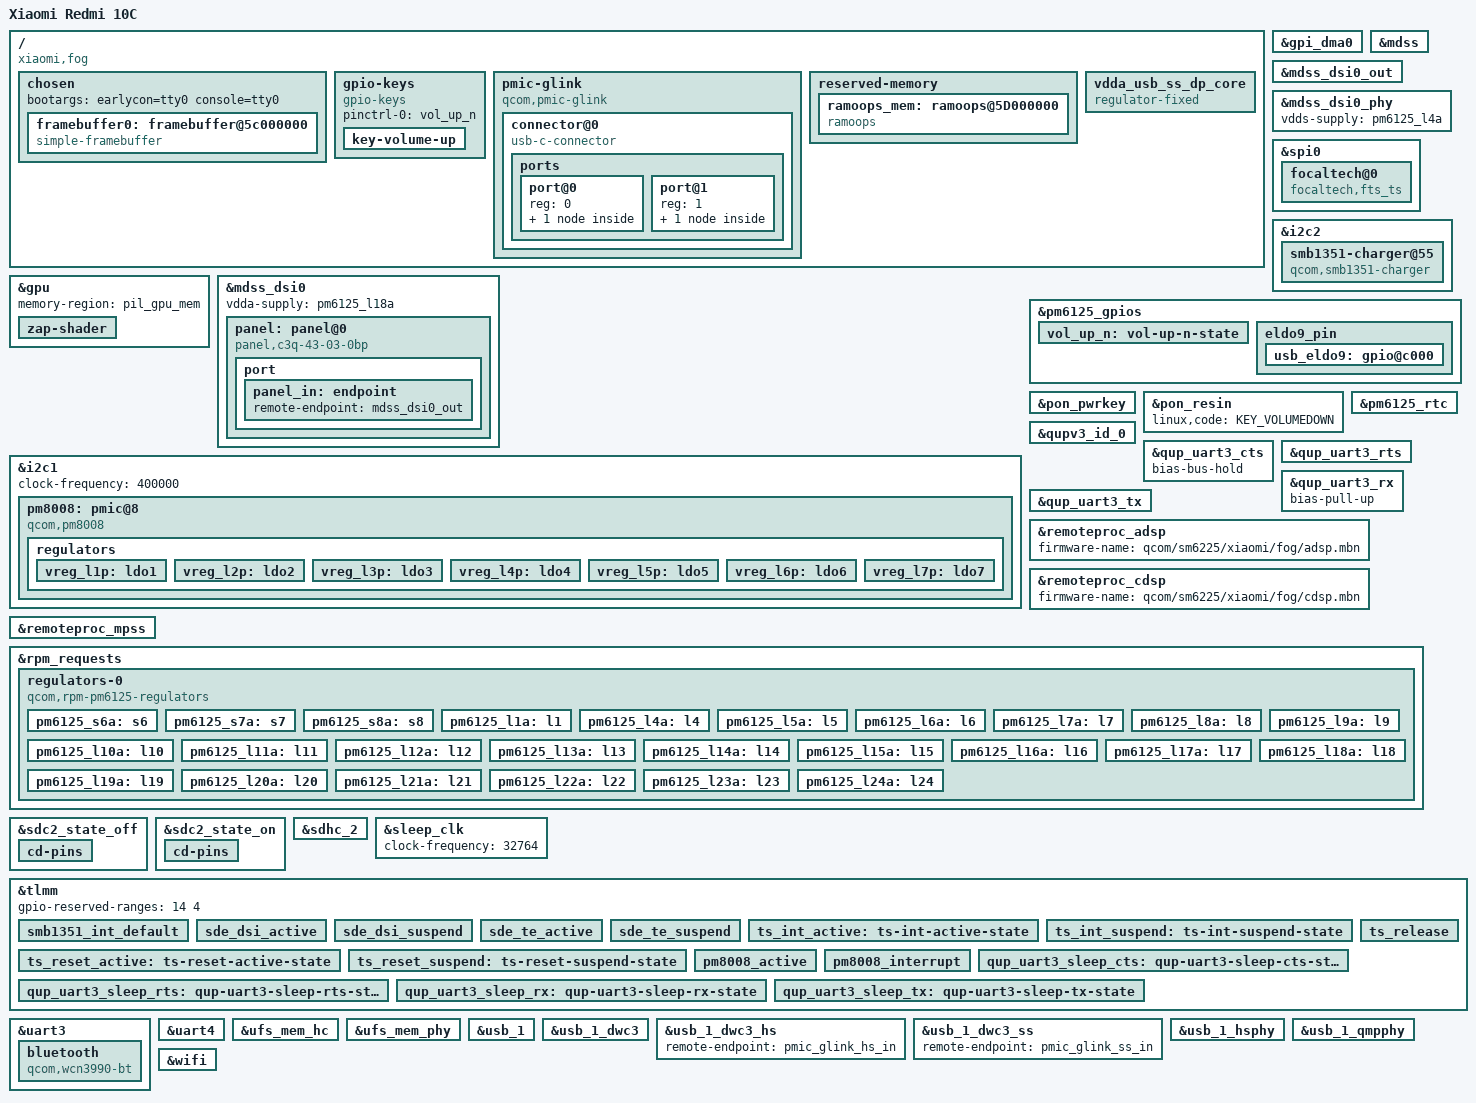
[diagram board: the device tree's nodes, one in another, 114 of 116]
// SPDX-License-Identifier: BSD-3-Clause
/*
 * Copyright (c) 2025, Statzar <azurestatzar@gmail.com>
 */

/dts-v1/;

#include "sm6225.dtsi"
#include "pm6125.dtsi"

#include <dt-bindings/arm/qcom,ids.h>
#include <dt-bindings/leds/common.h>
#include <dt-bindings/usb/pd.h>
#include <dt-bindings/input/input.h>
#include <dt-bindings/input/gpio-keys.h>

/ {
	/* required for bootloader to select correct board */
	qcom,board-id = <0x60022 0x00>;
	qcom,msm-id = <0x206 0x10000>;

	model = "Xiaomi Redmi 10C";
	compatible = "xiaomi,fog", "qcom,sm6225";
	chassis-type = "handset";

	chosen {
		bootargs = "earlycon=tty0 console=tty0";

		#address-cells = <2>;
		#size-cells = <2>;
		ranges;

		framebuffer0: framebuffer@5c000000 {
			compatible = "simple-framebuffer";
			reg = <0 0x5c000000 0 (1650 * 720 * 4)>;
			width = <720>;
			height = <1650>;
			stride = <(720 * 4)>;
			format = "a8r8g8b8";
			clocks = <&gcc GCC_DISP_HF_AXI_CLK>;
		};
	};

	gpio-keys {
		compatible = "gpio-keys";

		pinctrl-0 = <&vol_up_n>;
		pinctrl-names = "default";

		key-volume-up {
			label = "Volume Up";
			linux,code = <KEY_VOLUMEUP>;
			gpios = <&pm6125_gpios 5 GPIO_ACTIVE_LOW>;
			debounce-interval = <15>;
			linux,can-disable;
			wakeup-source;
		};
	};

	pmic-glink {
		compatible = "qcom,pmic-glink";

		#address-cells = <1>;
		#size-cells = <0>;

		connector@0 {
			compatible = "usb-c-connector";
			reg = <0>;
			power-role = "dual";
			data-role = "dual";
			self-powered;

			ports {
				#address-cells = <1>;
				#size-cells = <0>;

				port@0 {
					reg = <0>;

					pmic_glink_hs_in: endpoint {
						remote-endpoint = <&usb_1_dwc3_hs>;
					};
				};

				port@1 {
					reg = <1>;

					pmic_glink_ss_in: endpoint {
						remote-endpoint = <&usb_1_dwc3_ss>;
					};
				};
			};
		};
	};

	reserved-memory {
	        ramoops_mem:ramoops@5D000000 {
			compatible = "ramoops";
			reg = <0x00 0x5d000000 0x00 0x400000>;
			record-size = <0x80000>;
			pmsg-size = <0x200000>;
			console-size = <0x100000>;
		};
	};

	vdda_usb_ss_dp_core: vdda_usb_ss_dp_core {
		compatible = "regulator-fixed";
		regulator-name = "vdd_supply";
		regulator-min-microvolt = <880000>;
		regulator-max-microvolt = <880000>;
		enable-active-high;
		gpio = <&pm6125_gpios 1 GPIO_ACTIVE_HIGH>;
		pinctrl-names = "default";
		pinctrl-0 = <&usb_eldo9>;
	};

};

&gpi_dma0 {
	status = "okay";
};

&gpu {
	status = "okay";

	memory-region = <&pil_gpu_mem>;
	zap-shader {
		firmware-name = "qcom/sm6225/xiaomi/fog/a610_zap.mbn";
	};
};

&mdss {
	status = "okay";
};

&mdss_dsi0 {
	vdda-supply = <&pm6125_l18a>;
	status = "okay";

	panel: panel@0 {
		compatible = "panel,c3q-43-03-0bp";
		reg = <0>;

		reset-gpios = <&tlmm 82 GPIO_ACTIVE_LOW>;

		pinctrl-names = "panel_active", "panel_suspend";
		pinctrl-0 = <&sde_dsi_active>, <&sde_te_active>;
		pinctrl-1 = <&sde_dsi_suspend>, <&sde_te_suspend>;

		port {
			panel_in: endpoint {
				remote-endpoint = <&mdss_dsi0_out>;
			};
		};
	};
};

&mdss_dsi0_out {
	data-lanes = <0 1 2 3>;
	remote-endpoint = <&panel_in>;
};

&mdss_dsi0_phy {
	status = "okay";
	vdds-supply = <&pm6125_l4a>;
};

&spi0 {
	status = "okay";

	focaltech@0 {
		status = "okay";
		compatible = "focaltech,fts_ts";
		reg = <0x0>;
		spi-max-frequency = <9600000>;
		interrupt-parent = <&tlmm>;
		interrupts = <13 2>;
		focaltech,reset-gpio = <&tlmm 0x56 0x01>;
		focaltech,irq-gpio = <&tlmm 0x50 0x02>;
		focaltech,display-coords = <0 0 719 1649>;
		focaltech,max-touch-number = <10>;
		focaltech,ic-type = <0x8642081E>;

		pinctrl-names = "ts_int_active", "pmx_ts_suspend","pmx_ts_release";
		pinctrl-0 = <&ts_int_active>, <&ts_reset_active>;
		pinctrl-1 = <&ts_int_suspend>, <&ts_reset_suspend>;
		pinctrl-2 = <&ts_release>;

		firmware-name = "focaltech_ts_fw_xinli.bin";
	};
};

&i2c1 {
	clock-frequency = <400000>;
	status = "okay";

	pm8008: pmic@8 {
		compatible = "qcom,pm8008";
		reg = <0x8>;

		interrupt-parent = <&tlmm>;
		interrupts = <25 IRQ_TYPE_EDGE_RISING>;

		vdd-l1-l2-supply = <&pm6125_s6a>;
		vdd-l7-supply = <&pm6125_s7a>;

		pinctrl-names = "default";
		pinctrl-0 = <&pm8008_active>, <&pm8008_interrupt>;

		#thermal-sensor-cells = <0>;

		regulators {
			vreg_l1p: ldo1 {
				regulator-name = "vreg_l1p";
				regulator-min-microvolt = <1100000>;
				regulator-max-microvolt = <1300000>;
			};

			vreg_l2p: ldo2 {
				regulator-name = "vreg_l2p";
				regulator-min-microvolt = <950000>;
				regulator-max-microvolt = <1150000>;
			};

			vreg_l3p: ldo3 {
				regulator-name = "vreg_l3p";
				regulator-min-microvolt = <2700000>;
				regulator-max-microvolt = <2900000>;
			};

			vreg_l4p: ldo4 {
				regulator-name = "vreg_l4p";
				regulator-min-microvolt = <2700000>;
				regulator-max-microvolt = <2900000>;
			};

			vreg_l5p: ldo5 {
				regulator-name = "vreg_l5p";
				regulator-min-microvolt = <2700000>;
				regulator-max-microvolt = <2900000>;
			};

			vreg_l6p: ldo6 {
				regulator-name = "vreg_l6p";
				regulator-min-microvolt = <2700000>;
				regulator-max-microvolt = <2900000>;
			};

			vreg_l7p: ldo7 {
				regulator-name = "vreg_l7p";
				regulator-min-microvolt = <1650000>;
				regulator-max-microvolt = <1800000>;
			};
		};
	};
};

&i2c2 {
	status = "okay";

	smb1351-charger@55 {
		compatible = "qcom,smb1351-charger";
		reg = <0x55>;
		qcom,parallel-charger;
		qcom,float-voltage-mv = <4400>;
		qcom,recharge-mv = <100>;
		qcom,parallel-en-pin-polarity = <1>;

		interrupt-parent = <&tlmm>;
		interrupts = <84 IRQ_TYPE_EDGE_FALLING>;
		pinctrl-names = "default";
		pinctrl-0 = <&smb1351_int_default>;
		intr-gpios = <&tlmm 84 GPIO_ACTIVE_LOW>;
		dpdm-supply = <&usb_1_hsphy>;
	};
};

&pm6125_gpios {
	vol_up_n: vol-up-n-state {
		pins = "gpio5";
		function = "normal";
		power-source = <0>;
		bias-pull-up;
		input-enable;
	};

	eldo9_pin {
		usb_eldo9:gpio@c000 {
			pins = "gpio1";
			function = "normal";
			qcom,drive-strength = <2>;
			power-source = <0>;
			bias-disable;
			output-high;
		};
	};
};

&pon_pwrkey {
	status = "okay";
};

&pon_resin {
	linux,code = <KEY_VOLUMEDOWN>;
	status = "okay";
};

&pm6125_rtc {
	status = "okay";
};

&qupv3_id_0 {
	status = "okay";
};

&qup_uart3_cts {
	/*
	 * Configure a bias-bus-hold on CTS to lower power
	 * usage when Bluetooth is turned off. Bus hold will
	 * maintain a low power state regardless of whether
	 * the Bluetooth module drives the pin in either
	 * direction or leaves the pin fully unpowered.
	 */
	bias-bus-hold;
};

&qup_uart3_rts {
	/* We'll drive RTS, so no pull */
	drive-strength = <2>;
	bias-disable;
};

&qup_uart3_rx {
	/*
	 * Configure a pull-up on RX. This is needed to avoid
	 * garbage data when the TX pin of the Bluetooth module is
	 * in tri-state (module powered off or not driving the
	 * signal yet).
	 */
	bias-pull-up;
};

&qup_uart3_tx {
	/* We'll drive TX, so no pull */
	drive-strength = <2>;
	bias-disable;
};

&remoteproc_adsp {
	firmware-name = "qcom/sm6225/xiaomi/fog/adsp.mbn";
	status = "okay";
};

&remoteproc_cdsp {
	firmware-name = "qcom/sm6225/xiaomi/fog/cdsp.mbn";
	status = "okay";
};

&remoteproc_mpss {
	firmware-name = "qcom/sm6225/xiaomi/fog/modem.mbn";
	status = "okay";
};

&rpm_requests {
	regulators-0 {
		compatible = "qcom,rpm-pm6125-regulators";

		pm6125_s6a: s6 {
			regulator-min-microvolt = <400000>;
			regulator-max-microvolt = <1419000>;
		};

		pm6125_s7a: s7 {
			regulator-min-microvolt = <1569000>;
			regulator-max-microvolt = <2040000>;
		};

		pm6125_s8a: s8 {
			regulator-min-microvolt = <1060000>;
			regulator-max-microvolt = <1170000>;
		};

		pm6125_l1a: l1 {
			regulator-min-microvolt = <950000>;
			regulator-max-microvolt = <1150000>;
		};

		pm6125_l4a: l4 {
			regulator-min-microvolt = <720000>;
			regulator-max-microvolt = <1050000>;
		};

		pm6125_l5a: l5 {
			regulator-min-microvolt = <1650000>;
			regulator-max-microvolt = <3050000>;
			regulator-allow-set-load;
		};

		pm6125_l6a: l6 {
			regulator-min-microvolt = <570000>;
			regulator-max-microvolt = <650000>;
		};

		pm6125_l7a: l7 {
			regulator-min-microvolt = <1200000>;
			regulator-max-microvolt = <1300000>;
		};

		pm6125_l8a: l8 {
			regulator-min-microvolt = <400000>;
			regulator-max-microvolt = <728000>;
		};

		pm6125_l9a: l9 {
			regulator-min-microvolt = <1504000>;
			regulator-max-microvolt = <2000000>;
		};

		pm6125_l10a: l10 {
			regulator-min-microvolt = <1700000>;
			regulator-max-microvolt = <1900000>;
		};

		pm6125_l11a: l11 {
			regulator-min-microvolt = <1700000>;
			regulator-max-microvolt = <1950000>;
			regulator-allow-set-load;
		};

		pm6125_l12a: l12 {
			regulator-min-microvolt = <1620000>;
			regulator-max-microvolt = <1980000>;
		};

		pm6125_l13a: l13 {
			regulator-min-microvolt = <1504000>;
			regulator-max-microvolt = <2000000>;
		};

		pm6125_l14a: l14 {
			regulator-min-microvolt = <1700000>;
			regulator-max-microvolt = <1900000>;
		};

		pm6125_l15a: l15 {
			regulator-min-microvolt = <2700000>;
			regulator-max-microvolt = <3544000>;
		};

		pm6125_l16a: l16 {
			regulator-min-microvolt = <1700000>;
			regulator-max-microvolt = <1900000>;
		};

		pm6125_l17a: l17 {
			regulator-min-microvolt = <1220000>;
			regulator-max-microvolt = <1304000>;
		};

		pm6125_l18a: l18 {
			regulator-min-microvolt = <1100000>;
			regulator-max-microvolt = <1300000>;
		};

		pm6125_l19a: l19 {
			regulator-min-microvolt = <1620000>;
			regulator-max-microvolt = <3300000>;
		};

		pm6125_l20a: l20 {
			regulator-min-microvolt = <1620000>;
			regulator-max-microvolt = <3300000>;
		};

		pm6125_l21a: l21 {
			regulator-min-microvolt = <1600000>;
			regulator-max-microvolt = <3544000>;
		};

		pm6125_l22a: l22 {
			regulator-min-microvolt = <2950000>;
			regulator-max-microvolt = <3300000>;
		};

		pm6125_l23a: l23 {
			regulator-min-microvolt = <3200000>;
			regulator-max-microvolt = <3400000>;
		};

		pm6125_l24a: l24 {
			regulator-min-microvolt = <2700000>;
			regulator-max-microvolt = <3544000>;
			regulator-allow-set-load;
		};
	};
};

&sdc2_state_off {
	cd-pins {
		pins = "gpio88";
		function = "gpio";
		drive-strength = <2>;
		bias-disable;
	};
};

&sdc2_state_on {
	cd-pins {
		pins = "gpio88";
		function = "gpio";
		drive-strength = <2>;
		bias-pull-up;
	};
};

&sdhc_2 {
	pinctrl-0 = <&sdc2_state_on>;
	pinctrl-1 = <&sdc2_state_off>;
	pinctrl-names = "default", "sleep";

	cd-gpios = <&tlmm 88 GPIO_ACTIVE_LOW>;

	vmmc-supply = <&pm6125_l22a>;
	vqmmc-supply = <&pm6125_l5a>;

	status = "okay";
};

&sleep_clk {
	clock-frequency = <32764>;
};

&tlmm {
	gpio-reserved-ranges = <14 4>;

	smb1351_int_default: smb1351_int_default {
		pins = "gpio84";
		function = "gpio";
		drive-strength = <2>;
		bias-pull-up;
		input-enable;
	};

	sde_dsi_active: sde_dsi_active {
		pins = "gpio82";
		function = "gpio";
		drive-strength = <8>;
		bias-disable = <0>;
	};

	sde_dsi_suspend: sde_dsi_suspend {
		pins = "gpio82";
		function = "gpio";
		drive-strength = <2>;
		bias-pull-down;
	};

	sde_te_active: sde_te_active {
		pins = "gpio81";
		function = "mdp_vsync";
		drive-strength = <2>;
		bias-pull-down;
	};

	sde_te_suspend: sde_te_suspend {
		function = "mdp_vsync";
		pins = "gpio81";
		drive-strength = <2>;
		bias-pull-down;
	};

	ts_int_active: ts-int-active-state {
		pins = "gpio80";
		function = "gpio";
		drive-strength = <8>;
		bias-pull-up;
	};

	ts_int_suspend: ts-int-suspend-state {
		pins = "gpio80";
		function = "gpio";
		drive-strength = <2>;
		bias-pull-down;
	};

	ts_reset_active: ts-reset-active-state {
		pins = "gpio86";
		function = "gpio";
		drive-strength = <8>;
		bias-pull-up;
	};

	ts_reset_suspend: ts-reset-suspend-state {
		pins = "gpio86";
		function = "gpio";
		drive-strength = <2>;
		bias-pull-down;
	};

	ts_release: ts_release {
		pins = "gpio80", "gpio86";
		function = "gpio";
		drive-strength = <2>;
		bias-pull-down;
	};

	pm8008_active: pm8008_active {
		pins = "gpio26";
		function = "gpio";
		bias-pull-up;
		output-high;
		drive-strength = <2>;
	};

	pm8008_interrupt: pm8008_interrupt {
		pins = "gpio25";
		function = "gpio";
		bias-disable;
		input-enable;
	};

	qup_uart3_sleep_cts: qup-uart3-sleep-cts-state {
		pins = "gpio8";
		function = "gpio";
		/*
		 * Configure a bias-bus-hold on CTS to lower power
		 * usage when Bluetooth is turned off. Bus hold will
		 * maintain a low power state regardless of whether
		 * the Bluetooth module drives the pin in either
		 * direction or leaves the pin fully unpowered.
		 */
		bias-bus-hold;
	};

	qup_uart3_sleep_rts: qup-uart3-sleep-rts-state {
		pins = "gpio9";
		function = "gpio";
		/*
		 * Configure pull-down on RTS. As RTS is active low
		 * signal, pull it low to indicate the BT SoC that it
		 * can wakeup the system anytime from suspend state by
		 * pulling RX low (by sending wakeup bytes).
		 */
		bias-pull-down;
	};

	qup_uart3_sleep_rx: qup-uart3-sleep-rx-state {
		pins = "gpio11";
		function = "gpio";
		/*
		 * Configure a pull-up on RX. This is needed to avoid
		 * garbage data when the TX pin of the Bluetooth module
		 * is floating which may cause spurious wakeups.
		 */
		bias-pull-up;
	};

	qup_uart3_sleep_tx: qup-uart3-sleep-tx-state {
		pins = "gpio10";
		function = "gpio";
		/*
		 * Configure pull-up on TX when it isn't actively driven
		 * to prevent BT SoC from receiving garbage during sleep.
		 */
		bias-pull-up;
	};
};

&uart3 {
	/delete-property/ interrupts;
	interrupts-extended = <&intc GIC_SPI 330 IRQ_TYPE_LEVEL_HIGH>,
			      <&tlmm 11 IRQ_TYPE_LEVEL_HIGH>;

	pinctrl-names = "default", "sleep";
	pinctrl-1 = <&qup_uart3_sleep_cts>, <&qup_uart3_sleep_rts>, <&qup_uart3_sleep_tx>, <&qup_uart3_sleep_rx>;

	status = "okay";

	bluetooth {
		compatible = "qcom,wcn3990-bt";

		vddio-supply = <&pm6125_l9a>;
		vddxo-supply = <&pm6125_l16a>;
		vddrf-supply = <&pm6125_l17a>;
		vddch0-supply = <&pm6125_l23a>;
		max-speed = <3200000>;

		clocks = <&rpmcc RPM_SMD_RF_CLK2_PIN>;
	};
};

&uart4 {
	status = "okay";
};

&ufs_mem_hc {
	vcc-supply = <&pm6125_l24a>;
	vcc-max-microamp = <800000>;
	vccq2-supply = <&pm6125_l11a>;
	vccq2-max-microamp = <800000>;
	vdd-hba-supply = <&pm6125_l18a>;
	status = "okay";
};

&ufs_mem_phy {
	vdda-phy-supply = <&pm6125_l4a>;
	vdda-pll-supply = <&pm6125_l18a>;

	status = "okay";
};

&usb_1 {
	status = "okay";
};

&usb_1_dwc3 {
	dr_mode = "otg";
	maximum-speed = "high-speed";
	/* Remove USB3 phy */
	phys = <&usb_1_hsphy>;
	phy-names = "usb2-phy";
	usb-role-switch;
};

&usb_1_dwc3_hs {
	remote-endpoint = <&pmic_glink_hs_in>;
};

&usb_1_dwc3_ss {
	remote-endpoint = <&pmic_glink_ss_in>;
};

&usb_1_hsphy {
	vdd-supply = <&pm6125_l4a>;
	vdda-pll-supply = <&pm6125_l12a>;
	vdda-phy-dpdm-supply = <&pm6125_l15a>;
	status = "okay";
};

&usb_1_qmpphy {
	vdda-phy-supply = <&pm6125_l18a>;
	vdda-pll-supply = <&vdda_usb_ss_dp_core>;
	status = "okay";
};

&wifi {
	vdd-0.8-cx-mx-supply = <&pm6125_l8a>;
	vdd-1.8-xo-supply = <&pm6125_l16a>;
	vdd-1.3-rfa-supply = <&pm6125_l17a>;
	vdd-3.3-ch0-supply = <&pm6125_l23a>;

	status = "okay";
};
